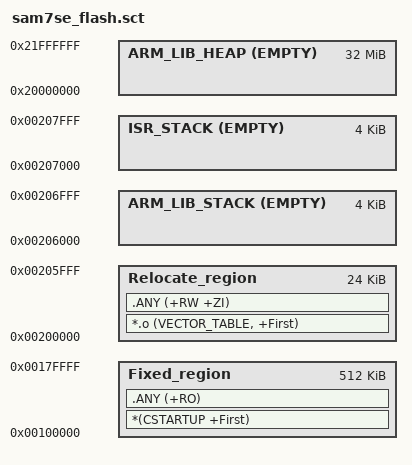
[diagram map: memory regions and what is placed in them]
;*****************************************************************
;* SAM7SE linker scatter file (running code from internal FLASH) *
;*****************************************************************
 
Load_region 0x00100000 0x80000
{
   Fixed_region 0x00100000 0x80000
   {
      *(CSTARTUP +First)
      .ANY (+RO)
   }

   Relocate_region 0x00200000 0x6000
   {
      *.o (VECTOR_TABLE, +First)   
      .ANY (+RW +ZI)
   }

   ARM_LIB_HEAP 0x20000000 EMPTY 0x2000000
   {
   }

   ARM_LIB_STACK 0x00207000 EMPTY -0x1000
   {
   }

   ISR_STACK 0x00208000 EMPTY -0x1000
   {
   }
}
